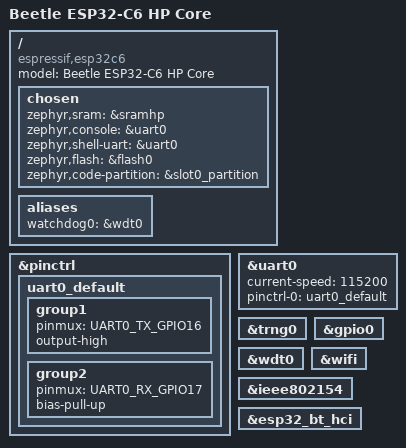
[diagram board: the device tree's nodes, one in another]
/*
 * SPDX-License-Identifier: Apache-2.0
 */

/dts-v1/;

#include <espressif/esp32c6/esp32c6_wroom_n4.dtsi>
#include <zephyr/dt-bindings/input/input-event-codes.h>
#include <zephyr/dt-bindings/pinctrl/esp-pinctrl-common.h>
#include <zephyr/dt-bindings/pinctrl/esp32c6-pinctrl.h>
#include <zephyr/dt-bindings/pinctrl/esp32c6-gpio-sigmap.h>
#include <espressif/partitions_0x0_default.dtsi>

/ {
	model = "Beetle ESP32-C6 HP Core";
	compatible = "espressif,esp32c6";

	chosen {
		zephyr,sram = &sramhp;
		zephyr,console = &uart0;
		zephyr,shell-uart = &uart0;
		zephyr,flash = &flash0;
		zephyr,code-partition = &slot0_partition;
	};

	aliases {
		watchdog0 = &wdt0;
	};
};

&pinctrl {
	uart0_default: uart0_default {
		group1 {
			pinmux = <UART0_TX_GPIO16>;
			output-high;
		};

		group2 {
			pinmux = <UART0_RX_GPIO17>;
			bias-pull-up;
		};
	};
};

&uart0 {
	status = "okay";
	current-speed = <115200>;
	pinctrl-0 = <&uart0_default>;
	pinctrl-names = "default";
};

&trng0 {
	status = "okay";
};

&gpio0 {
	status = "okay";
};

&wdt0 {
	status = "okay";
};

&wifi {
	status = "okay";
};

&ieee802154 {
	status = "okay";
};

&esp32_bt_hci {
	status = "okay";
};
